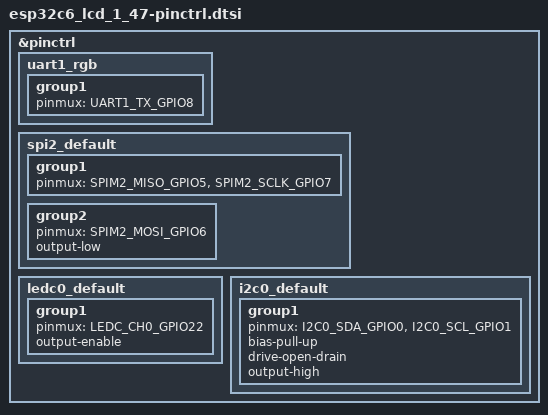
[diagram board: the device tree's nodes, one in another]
/*
 * Copyright (c) 2026 Embeint Holdings Pty Ltd
 * SPDX-License-Identifier: FSL-1.1-ALv2
 */

#include <zephyr/dt-bindings/pinctrl/esp-pinctrl-common.h>
#include <zephyr/dt-bindings/pinctrl/esp32c6-pinctrl.h>
#include <zephyr/dt-bindings/pinctrl/esp32c6-gpio-sigmap.h>

&pinctrl {
	uart1_rgb: uart1_rgb {
		group1 {
			pinmux = <UART1_TX_GPIO8>;
		};
	};

	spi2_default: spi2_default {
		group1 {
			pinmux = <SPIM2_MISO_GPIO5>, <SPIM2_SCLK_GPIO7>;
		};
		group2 {
			pinmux = <SPIM2_MOSI_GPIO6>;
			output-low;
		};
	};

	ledc0_default: ledc0_default {
		group1 {
			pinmux = <LEDC_CH0_GPIO22>;
			output-enable;
		};
	};

	i2c0_default: i2c0_default {
		group1 {
			pinmux = <I2C0_SDA_GPIO0>, <I2C0_SCL_GPIO1>;
			bias-pull-up;
			drive-open-drain;
			output-high;
		};
	};
};
